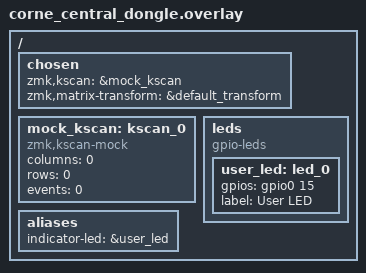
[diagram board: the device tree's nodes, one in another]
/*
 * Copyright (c) 2020 Pete Johanson
 *
 * SPDX-License-Identifier: MIT
 */

#include "corne.dtsi"

/ {
    chosen {
        zmk,kscan = &mock_kscan;
        zmk,matrix-transform = &default_transform;
    };

    mock_kscan: kscan_0 {
        compatible = "zmk,kscan-mock";
        columns = <0>;
        rows = <0>;
        events = <0>;
    };

    leds {
        compatible = "gpio-leds";
        user_led: led_0 {
            gpios = <&gpio0 15 GPIO_ACTIVE_HIGH>;
            label = "User LED";
        };
    };

    aliases {
        indicator-led = &user_led;
    };
};
